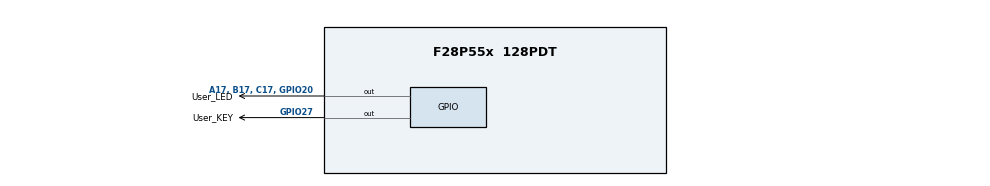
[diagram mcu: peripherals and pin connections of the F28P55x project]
/**
 * @cliArgs --device "F28P55x" --part "F28P55x_128PDT" --package "128PDT" --context "system" --product "C2000WARE@5.05.00.00"
 * @versions {"tool":"1.24.0+4110"}
 */

/**
 * Import the modules used in this configuration.
 */
const gpio             = scripting.addModule("/driverlib/gpio.js", {}, false);
const gpio1            = gpio.addInstance();
const gpio2            = gpio.addInstance();
const inputxbar_input  = scripting.addModule("/driverlib/inputxbar_input.js", {}, false);
const inputxbar_input1 = inputxbar_input.addInstance();

/**
 * Write custom configuration values to the imported modules.
 */
gpio1.$name                     = "User_KEY";
gpio1.qualMode                  = "GPIO_QUAL_6SAMPLE";
gpio1.useInterrupt              = true;
gpio1.gpioPin.$assign           = "GPIO27";
gpio1.xint.enableInt            = true;
gpio1.xint.registerInterrupts   = true;
gpio1.xint.xInt.enableInterrupt = true;

gpio2.$name           = "User_LED";
gpio2.direction       = "GPIO_DIR_MODE_OUT";
gpio2.gpioPin.$assign = "A17, B17, C17, GPIO20";

inputxbar_input1.$name         = "myINPUTXBARINPUT0";
gpio1.xint.inputxbar           = inputxbar_input1;
inputxbar_input1.inputxbarGpio = "GPIO27";
